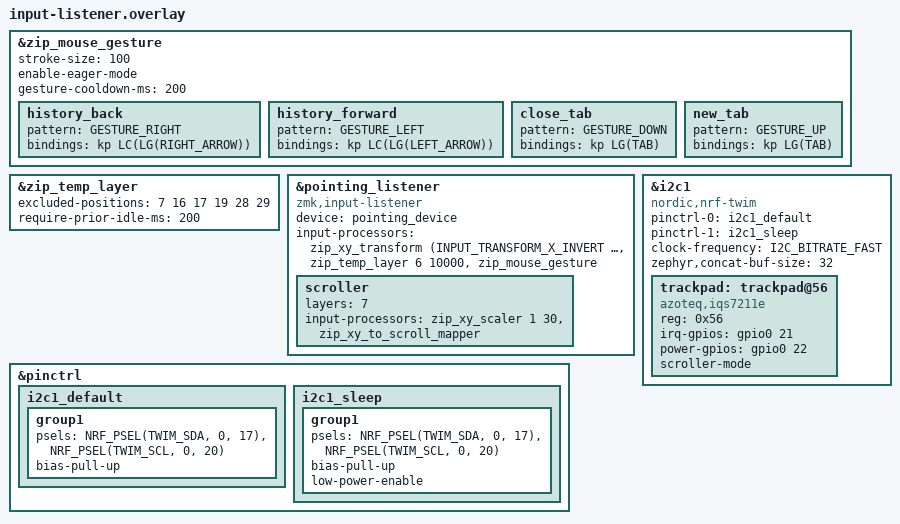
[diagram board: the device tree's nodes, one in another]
#include <mouse-gesture.dtsi>

// マウスジェスチャーbindings定義
&zip_mouse_gesture {
    stroke-size = <100>; // Optional (default: 200)
    enable-eager-mode; // Optional, but recommended
    gesture-cooldown-ms = <200>;

    history_back {
        pattern = <GESTURE_RIGHT>;
        bindings = <&kp LC(LG(RIGHT_ARROW))>;
    };

    history_forward {
        pattern = <GESTURE_LEFT>;
        bindings = <&kp LC(LG(LEFT_ARROW))>;
    };

    close_tab {
        pattern = <GESTURE_DOWN>;
        bindings = <&kp LG(TAB)>;
    };

    new_tab {
        pattern = <GESTURE_UP>;
        bindings = <&kp LG(TAB)>;
    };
};

&zip_temp_layer {
    excluded-positions = <7 16 17 19 28 29>;    // AML除外定義
    require-prior-idle-ms = <200>;           // AML誤爆防止
};

&pointing_listener {
    status = "okay";
    compatible = "zmk,input-listener";
    device = <&pointing_device>;
    input-processors = <&zip_xy_transform (INPUT_TRANSFORM_X_INVERT | INPUT_TRANSFORM_Y_INVERT)>,
                        <&zip_temp_layer 6 10000>,    // AML用
                        <&zip_mouse_gesture>;        // マウスジェスチャー用
    scroller {        // スクローラー用
        layers = <7>;
        input-processors = <&zip_xy_scaler 1 30>,
                           <&zip_xy_to_scroll_mapper>;
    };
};

// トラックパッド用
&pinctrl {
    i2c1_default: i2c1_default {
        group1 {
            psels = <NRF_PSEL(TWIM_SDA, 0, 17)>,
                    <NRF_PSEL(TWIM_SCL, 0, 20)>;
            bias-pull-up;
        };
    };

    i2c1_sleep: i2c1_sleep {
        group1 {
            psels = <NRF_PSEL(TWIM_SDA, 0, 17)>,
                    <NRF_PSEL(TWIM_SCL, 0, 20)>;
            bias-pull-up;
            low-power-enable;
        };
    };
};

&i2c1 {
    status = "okay";
    compatible = "nordic,nrf-twim";
    pinctrl-0 = <&i2c1_default>;
    pinctrl-1 = <&i2c1_sleep>;
    pinctrl-names = "default", "sleep";
    clock-frequency = <I2C_BITRATE_FAST>;
    zephyr,concat-buf-size = <32>;

    trackpad: trackpad@56 {
        status = "okay";
        compatible = "azoteq,iqs7211e";
        reg = <0x56>;
        irq-gpios = <&gpio0 21 GPIO_PULL_UP>;
        power-gpios = <&gpio0 22 GPIO_ACTIVE_HIGH>;
        scroller-mode;
        // v-invert;
    };
};

